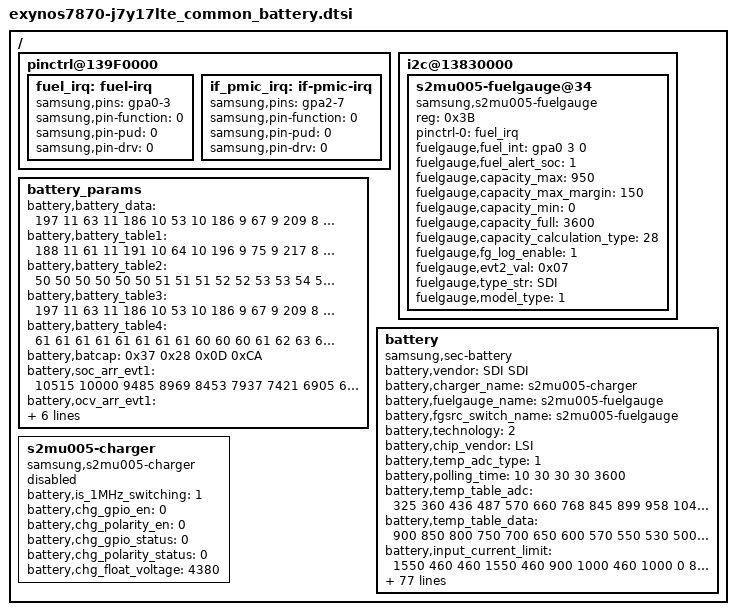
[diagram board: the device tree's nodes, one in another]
/*
 * SAMSUNG UNIVERSAL5433 board device tree source
 *
 * Copyright (c) 2013 Samsung Electronics Co., Ltd.
 *		http://www.samsung.com
 *
 * This program is free software; you can redistribute it and/or modify
 * it under the terms of the GNU General Public License version 2 as
 * published by the Free Software Foundation.
*/

/ {
	pinctrl@139F0000 {
		fuel_irq: fuel-irq {
			samsung,pins = "gpa0-3";
			samsung,pin-function = <0>;
			samsung,pin-pud = <0>;
			samsung,pin-drv = <0>;
		};
	};

	pinctrl@139F0000 {
		if_pmic_irq: if-pmic-irq {
			samsung,pins = "gpa2-7";
			samsung,pin-function = <0>;
			samsung,pin-pud = <0>;
			samsung,pin-drv = <0>;
		};
	};

	i2c@13830000 {
		status = "okay";
		s2mu005-fuelgauge@34 {
			compatible = "samsung,s2mu005-fuelgauge";
			reg = <0x3B>;
			pinctrl-names = "default";
			pinctrl-0 = <&fuel_irq>;
			fuelgauge,fuel_int = <&gpa0 3 0>;
			fuelgauge,fuel_alert_soc = <1>;
			fuelgauge,capacity_max = <950>;
			fuelgauge,capacity_max_margin = <150>;
			fuelgauge,capacity_min = <0>;
			fuelgauge,capacity_full = <3600>;
			fuelgauge,capacity_calculation_type = <28>;
			fuelgauge,fg_log_enable = <1>;
			fuelgauge,evt2_val = <0x07>;
			fuelgauge,type_str = "SDI";
			fuelgauge,model_type = <1>;
		};
	};

	battery_params {
			battery,battery_data = 
				<
				/***** battery data for 4.35 *****/
				/* battery,battery_table3 */
				197 11 63 11 186 10 53 10 186 9
				67 9 209 8 102 8 3 8 173 7
				75 7 233 6 174 6 130 6 95 6
				66 6 32 6 244 5 188 5 138 5
				240 4 146 1 237 8 126 8 15 8
				160 7 49 7 195 6 84 6 229 5
				118 5 7 5 153 4 42 4 187 3
				76 3 222 2 111 2 0 2 145 1
				34 1 180 0 69 0 214 15
				
				/* battery,battery_table4 */
				61 61 61 61 61 61 61 61 60 60
				60 61 62 63 63 64 65 67 70 76
				96 174

				/* battery,batcap */
				0x37 0x28 0x0D 0xCA /* [0x0F] [0x0E] [0x11] [0x10] */

				/* battery,accum */ 
				0xAD 0x07 /* [0x44] [0x45] */

				/* battery,soc_arr_val */
				11155 10614 10073 9532 8991 8450 7909 7368 6827 6286 5745 5204 4664 4123 3582 3041 2500 1959 1418 877 336 (-205)
				
				/* battery,ocv_arr_val */
				44710 44058 43406 42757 42156 41575 41021 40500 40016 39595 39117 38638 38351 38136 37965 37820 37654 37444 37170 36926 36173 31965


				/***** battery data for 4.33 *****/
				/* battery,battery_table3 */
				82 11 213 10 87 10 220 9 108 9
				0 9 157 8 55 8 204 7 141 7
				44 7 218 6 166 6 127 6 94 6
				66 6 31 6 248 5 192 5 142 5
				82 5 151 1 216 8 105 8 251 7
				140 7 30 7 175 6 65 6 211 5
				100 5 246 4 135 4 25 4 170 3
				60 3 205 2 95 2 240 1 130 1
				19 1 165 0 54 0 200 15
				
				/* battery,battery_table4 */
				55 55 55 56 55 55 55 55 55 54
				54 54 55 55 55 56 57 58 61 64
				71 154

				/* battery,batcap */
				0x33 0x90 0x0C 0xE4 /* [0x0F] [0x0E] [0x11] [0x10] */
				/* battery,accum */
				0xAD 0x07 /* [0x44] [0x45] */

				/* battery,soc_arr_val */
				11053 10513 9975 9435 8896 8356 7816 7278 6738 6199 5659 5120 4581 4041 3502 2962 2423 1884 1344 805 265 (-274)
				/* battery,ocv_arr_val */
				44149 43538 42927 42322 41776 41251 40769 40271 39746 39437 38967 38565 38313 38118 37961 37822 37651 37459 37188 36943 36651 31988
		
				/***** battery data for 4.31 *****/
				/* battery,battery_table3 */
				34 11 168 10 46 10 182 9 74 9
				227 8 131 8 12 8 188 7 120 7
				23 7 207 6 159 6 121 6 90 6
				63 6 29 6 245 5 189 5 144 5
				62 5 124 1 216 8 105 8 251 7
				140 7 30 7 176 6 65 6 211 5
				100 5 246 4 135 4 25 4 170 3
				60 3 205 2 95 2 241 1 130 1
				20 1 165 0 55 0 200 15

				/* battery,battery_table4 */
				60 60 60 60 59 59 58 59 58 58
				58 58 59 59 60 61 62 62 62 65
				73 154
				
				/* battery,batcap */                                  
				0x33 0x40 0x0C 0xD0 /* [0x0F] [0x0E] [0x11] [0x10] */ 
				/* battery,accum */
				0xAD 0x07 /* [0x44] [0x45] */

				/* battery,soc_arr_val */
				11054 10515 9976 9436 8897 8358 7818 7279 6740 6200 5661 5122 4582 4043 3503 2964 2425 1885 1346 806 267 (-272)
				/* battery,ocv_arr_val */
				43915 43320 42727 42139 41611 41108 40639 40058 39668 39336 38864 38509 38275 38091 37942 37810 37640 37448 37175 36952 36552 31856


				/***** battery data for 4.29 *****/
				/* batterybattery_table3 */
				243 10 126 10 9 10 149 9 44 9
				201 8 111 8 240 7 175 7 97 7
				2 7 197 6 152 6 116 6 87 6
				59 6 22 6 239 5 183 5 140 5
				68 5 154 1 181 8 72 8 219 7
				111 7 2 7 149 6 40 6 187 5
				78 5 225 4 116 4 8 4 155 3
				46 3 193 2 84 2 231 1 122 1
				14 1 161 0 52 0 199 15

				/* batterybattery_table4 */
				55 55 55 55 55 56 55 56 56 55
				55 55 56 57 57 58 59 60 63 67
				73 154

				/* batterybatcap */                                  
				0x32 0xA0 0x0C 0xA0 /* [0x0F] [0x0E] [0x11] [0x10] */ 
				/* batteryaccum */
				0xAD 0x07 /* [0x44] [0x45] */

				/* batterysoc_arr_val */
				10885 10353 9821 9290 8758 8227 7695 7164 6632 6101 5568 5038 4506 3973 3443 2911 2380 1848 1317 785 254 (-278)

				/* batteryocv_arr_val */
				43685 43114 42543 41977 41464 40984 40540 39922 39604 39222 38760 38460 38242 38067 37923 37786 37607 37419 37145 36936 36582 32000

				/***** battery data for 4.24 *****/
				/* battery,battery_table3 */
				126 10 18 10 166 9 59 9 220 8
				136 8 10 8 192 7 134 7 38 7
				221 6 173 6 135 6 104 6 77 6
				49 6 14 6 228 5 173 5 137 5
				238 4 70 1 181 8 72 8 220 7
				111 7 3 7 150 6 42 6 189 5
				80 5 228 4 119 4 11 4 158 3
				50 3 197 2 88 2 236 1 127 1
				19 1 166 0 58 0 205 15
								
				/* battery,battery_table4 */
				56 56 56 56 56 56 57 57 56 55
				56 56 57 58 59 60 60 62 65 70
				77 154
				
				/* battery,batcap */                                  
				0x30 0xE8 0x0C 0x3A /* [0x0F] [0x0E] [0x11] [0x10] */ 
				/* battery,accum */
				0xAD 0x07 /* [0x44] [0x45] */

				/* battery,soc_arr_val */
				10883 10353 9823 9293 8763 8233 7703 7173 6643 6113 5583 5053 4522 3992 3462 2932 2402 1872 1342 812 282 (-248)
				
				/* battery,ocv_arr_val */
				43115 42589 42063 41540 41072 40666 40050 39690 39406 38938 38579 38345 38159 38007 37878 37739 37569 37365 37095 36919 36164 31594
				>;
				
			battery,battery_table1 = <188 11 61 11 191 10 64 10 196 9
					75 9 217 8 110 8 13 8 173 7
					66 7 235 6 177 6 132 6 96 6
					67 6 31 6 242 5 164 5 124 5
					23 5 144 1 216 8 105 8 251 7
					141 7 30 7 176 6 65 6 211 5
					101 5 246 4 136 4 25 4 171 3
					60 3 206 2 95 2 241 1 131 1
					20 1 166 0 55 0 201 15>;

			battery,battery_table2 = <50 50 50 50 50 50 51 51 51 52
					52 53 53 54 54 55 55 56 57 59
					63 154>;

			battery,battery_table3 = <197 11 63 11 186 10 53 10 186 9
					67 9 209 8 102 8 3 8 173 7
					75 7 233 6 174 6 130 6 95 6
					66 6 32 6 244 5 188 5 138 5
					240 4 146 1 237 8 126 8 15 8
					160 7 49 7 195 6 84 6 229 5
					118 5 7 5 153 4 42 4 187 3
					76 3 222 2 111 2 0 2 145 1
					34 1 180 0 69 0 214 15>;

			battery,battery_table4 = <61 61 61 61 61 61 61 61 60 60
					60 61 62 63 63 64 65 67 70 76
					96 174>;

			battery,batcap = <0x37 0x28 0x0D 0xCA>; /* [0x0F] [0x0E] [0x11] [0x10] */

			battery,soc_arr_evt1 = <10515 10000 9485 8969 8453 7937 7421 6905 6389 5873 5358 4842 4326 3810 3294 2778 2263 1747 1231 716 200 (-269)>;
			battery,ocv_arr_evt1 = <44051 43459 42867 42288 41716 41175 40664 40199 39779 39268 38784 38482 38250 38059 37906 37778 37594 37368 36957 36835 36289 31955>;

			battery,soc_arr_evt2 = <11155 10614 10073 9532 8991 8450 7909 7368 6827 6286 5745 5204 4664 4123 3582 3041 2500 1959 1418 877 336 (-205)>;
			battery,ocv_arr_evt2 = <44710 44058 43406 42757 42156 41575 41021 40500 40016 39595 39117 38638 38351 38136 37965 37820 37654 37444 37170 36926 36173 31965>;

			battery,FG_Accumulative_rate_evt2 = <0xAD 0x07>;
	};

	battery {
		status = "okay";

		pinctrl-names = "default";

		compatible = "samsung,sec-battery";
		battery,vendor = "SDI SDI";
		battery,charger_name = "s2mu005-charger";
		battery,fuelgauge_name = "s2mu005-fuelgauge";
		battery,fgsrc_switch_name = "s2mu005-fuelgauge";
		battery,technology = <2>; /* POWER_SUPPLY_TECHNOLOGY_LION */

		battery,chip_vendor = "LSI";
		battery,temp_adc_type = <1>; /* SEC_BATTERY_ADC_TYPE_AP */

		battery,polling_time = <10 30 30 30 3600>;

		battery,temp_table_adc = <325 360 436 487 570 660 768 845 899 958 1045 1107 1141 1209 1278 1315 1388 1504 1591
								 1679 1806 1936 2038 2266 2487 2711 2912 2989 3099 3201 3257 3314 3396 3515 3606>;

		battery,temp_table_data = <900 850 800 750 700 650 600 570 550 530 500 480 470 450 430 420 400 370 350 
								 330 300 270 250 200 150 100 50 30 0 (-30) (-50) (-70) (-100) (-150) (-200)>;

		battery,input_current_limit = <1550 460 460 1550 460 900 1000 460 1000 0 820 820 820 1900 1550 0 0 400 700 1300 300 1000 1550 0 1550 1550 1000 1550 80 1550 1550 1400 1000 1000 820 820 820 820 1550 1550 1550 1550 1550 1550>;
		battery,fast_charging_current = <1775 0 0 1775 460 1200 1000 460 1200 0 1200 1200 1200 1700 1775 0 0 400 700 1300 300 1000 1500 0 1775 1775 1000 1775 80 1775 1000 1400 0 1000 1200 1200 1200 1200 1775 1775 1775 1775 1775 1775>;
		battery,full_check_current_1st = <360 0 0 360 360 360 360 360 360 0 360 360 360 360 360 0 0 360 360 360 360 360 360 0 360 360 360 360 0 360 360 360 0 360 360 360 360 360 360 360 360 360 360 360>;
		battery,full_check_current_2nd = <180 0 0 180 180 180 180 180 180 0 180 180 180 180 180 0 0 180 180 180 180 180 180 0 180 180 180 180 0 180 180 180 0 180 180 180 180 180 180 180 180 180 180 180>;

		battery,wireless_cc_cv = <86>;
		battery,inbat_voltage = <1>;

		battery,inbat_voltage_table_adc = <2884 2853 2821 2793 2765 2735 2708 2681 2650 2620
						2590 2559 2530 2500 2471 2440 2418 2386 2359 2329
						2298 2266 2239 2209 2181 2155 2125 2096>;
		battery,inbat_voltage_table_data = <4350 4300 4250 4200 4150 4100 4050 4000 3950 3900
						3850 3800 3750 3700 3650 3600 3550 3500 3450 3400
						3350 3300 3250 3200 3150 3100 3050 3000>;

		battery,adc_check_count = <5>;

		battery,cable_check_type = <4>; /* SEC_BATTERY_CABLE_CHECK_PSY */
		battery,cable_source_type = <1>; /* SEC_BATTERY_CABLE_SOURCE_EXTERNAL */
		battery,polling_type = <1>; /* SEC_BATTERY_MONITOR_ALARM */
		battery,monitor_initial_count = <0>;

		battery,battery_check_type = <5>; /* SEC_BATTERY_CHECK_CHARGER */
		battery,check_count = <0>;

		battery,ovp_uvlo_check_type = <3>; /* SEC_BATTERY_OVP_UVLO_CHGPOLLING */

		battery,check_adc_max = <1440>;
		battery,check_adc_min = <0>;

		battery,thermal_source = <2>; /* SEC_BATTERY_THERMAL_SOURCE_ADC */

		battery,temp_check_type = <2>; /* SEC_BATTERY_TEMP_CHECK_TEMP */
		battery,temp_check_count = <1>;
		battery,temp_highlimit_threshold_normal = <800>;
		battery,temp_highlimit_recovery_normal = <750>;
		battery,temp_high_threshold_normal = <500>;
		battery,temp_high_recovery_normal = <450>;
		battery,temp_low_threshold_normal = <0>;
		battery,temp_low_recovery_normal = <50>;
		battery,temp_highlimit_threshold_lpm = <800>;
		battery,temp_highlimit_recovery_lpm = <750>;
		battery,temp_high_threshold_lpm = <500>;
		battery,temp_high_recovery_lpm = <450>;
		battery,temp_low_threshold_lpm = <0>;
		battery,temp_low_recovery_lpm = <50>;

		battery,full_check_type = <2>; /* SEC_BATTERY_FULLCHARGED_FG_CURRENT */
		battery,full_check_type_2nd = <2>; /* SEC_BATTERY_FULLCHARGED_FG_CURRENT */
		battery,full_check_count = <1>;
		battery,chg_gpio_full_check = <0>;
		battery,chg_polarity_full_check = <1>;

		/* SEC_BATTERY_FULL_CONDITION_SOC |
		   SEC_BATTERY_FULL_CONDITION_NOTIMEFULL |
		   SEC_BATTERY_FULL_CONDITION_VCELL */
		battery,full_condition_type = <15>;
		battery,full_condition_soc = <93>;
		battery,full_condition_vcell = <4290>;

		battery,recharge_check_count = <2>;
		battery,recharge_condition_type = <4>; /* SEC_BATTERY_RECHARGE_CONDITION_VCELL */
		battery,recharge_condition_soc = <98>;
		battery,recharge_condition_vcell = <4250>;
		
		battery,expired_time = <16200>;
		battery,recharginig_expired_time = <5400>;
		battery,standard_curr = <1775>;
		battery,battery_full_capacity = <3600>;

		battery,charging_total_time = <21600>;
		battery,recharging_total_time = <5400>;
		battery,charging_reset_time = <0>;

		battery,chg_float_voltage = <4350>;


		battery,swelling_high_temp_block = <410>;
		battery,swelling_high_temp_recov = <390>;
		battery,swelling_low_temp_2step_mode = <1>;
		battery,swelling_low_temp_block_1st = <150>;
		battery,swelling_low_temp_recov_1st = <200>;
		battery,swelling_low_temp_block_2nd = <50>;
		battery,swelling_low_temp_recov_2nd = <100>;
		battery,swelling_low_temp_current = <1050>;
		battery,swelling_low_temp_topoff = <180>;
		battery,swelling_high_temp_current = <1600>;
		battery,swelling_high_temp_topoff = <180>;
		battery,swelling_drop_float_voltage = <4150>;
		battery,swelling_high_rechg_voltage = <4000>;
		battery,swelling_low_rechg_voltage = <4000>;

		battery,siop_input_limit_current = <1550>;
		battery,siop_charging_limit_current = <1000>;

		/* cycle, chg_float_voltage, recharge_condition_vcell, full_condition_vcell, full_condition_soc */
        battery,age_data = <0 4350 4250 4250 93
                        200 4330 4230 4230 92
                        250 4310 4210 4210 91
                        300 4290 4190 4190 90
                        1000 4240 4140 4140 89>;

		io-channels = <&exynos_adc 1>,<&exynos_adc 3>;
		io-channel-names = "adc-temp","adc-in-bat";
		#io-channel-cells = <1>;
		io-channel-ranges;
	};

	s2mu005-charger {
		status = "disable";
		compatible = "samsung,s2mu005-charger";
		battery,is_1MHz_switching = <1>;
		battery,chg_gpio_en = <0>;
		battery,chg_polarity_en = <0>;
		battery,chg_gpio_status = <0>;
		battery,chg_polarity_status = <0>;
		battery,chg_float_voltage = <4380>;
	};
};
